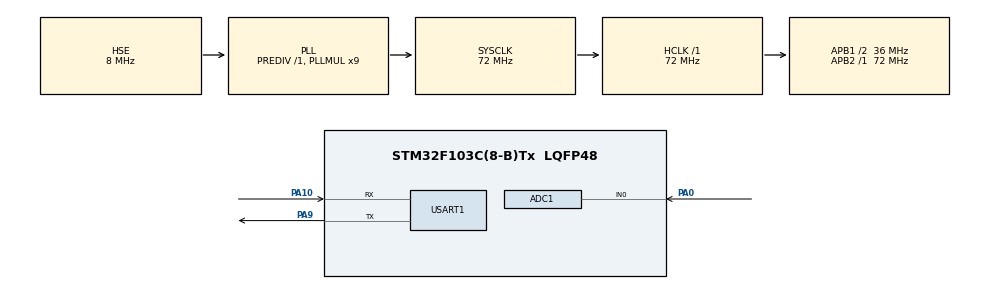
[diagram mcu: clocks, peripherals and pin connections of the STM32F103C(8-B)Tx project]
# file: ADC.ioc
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ADC1.Channel-0\#ChannelRegularConversion=ADC_CHANNEL_0
ADC1.ExternalTrigConv=ADC_EXTERNALTRIGCONV_T3_TRGO
ADC1.NbrOfConversionFlag=1
ADC1.Rank-0\#ChannelRegularConversion=1
ADC1.SamplingTime-0\#ChannelRegularConversion=ADC_SAMPLETIME_1CYCLE_5
ADC1.master=1
Dma.ADC1.0.Direction=DMA_PERIPH_TO_MEMORY
Dma.ADC1.0.Instance=DMA1_Channel1
Dma.ADC1.0.MemDataAlignment=DMA_MDATAALIGN_HALFWORD
Dma.ADC1.0.MemInc=DMA_MINC_ENABLE
Dma.ADC1.0.Mode=DMA_CIRCULAR
Dma.ADC1.0.PeriphDataAlignment=DMA_PDATAALIGN_HALFWORD
Dma.ADC1.0.PeriphInc=DMA_PINC_DISABLE
Dma.ADC1.0.Priority=DMA_PRIORITY_LOW
Dma.Request0=ADC1
Dma.Request1=USART1_RX
Dma.Request2=USART1_TX
Dma.USART1_RX.1.Direction=DMA_PERIPH_TO_MEMORY
Dma.USART1_RX.1.Instance=DMA1_Channel5
Dma.USART1_RX.1.MemDataAlignment=DMA_MDATAALIGN_BYTE
Dma.USART1_RX.1.MemInc=DMA_MINC_ENABLE
Dma.USART1_RX.1.Mode=DMA_NORMAL
Dma.USART1_RX.1.PeriphDataAlignment=DMA_PDATAALIGN_BYTE
Dma.USART1_RX.1.PeriphInc=DMA_PINC_DISABLE
Dma.USART1_RX.1.Priority=DMA_PRIORITY_LOW
Dma.USART1_TX.2.Direction=DMA_MEMORY_TO_PERIPH
Dma.USART1_TX.2.Instance=DMA1_Channel4
Dma.USART1_TX.2.MemDataAlignment=DMA_MDATAALIGN_BYTE
Dma.USART1_TX.2.MemInc=DMA_MINC_ENABLE
Dma.USART1_TX.2.Mode=DMA_NORMAL
Dma.USART1_TX.2.PeriphDataAlignment=DMA_PDATAALIGN_BYTE
Dma.USART1_TX.2.PeriphInc=DMA_PINC_DISABLE
Dma.USART1_TX.2.Priority=DMA_PRIORITY_LOW
Mcu.Family=STM32F1
Mcu.Name=STM32F103C(8-B)Tx
Mcu.Package=LQFP48
NVIC.ADC1_2_IRQn=true\:0\:0\:false\:false\:true\:true\:true
NVIC.DMA1_Channel1_IRQn=true\:0\:0\:false\:false\:true\:false\:true
NVIC.DMA1_Channel4_IRQn=true\:0\:0\:false\:false\:true\:false\:true
NVIC.DMA1_Channel5_IRQn=true\:0\:0\:false\:false\:true\:false\:true
NVIC.PriorityGroup=NVIC_PRIORITYGROUP_4
NVIC.TIM3_IRQn=true\:0\:0\:false\:false\:true\:true\:true
NVIC.USART1_IRQn=true\:0\:0\:false\:false\:true\:true\:true
PA0-WKUP.Signal=ADCx_IN0
PA10.Mode=Asynchronous
PA10.Signal=USART1_RX
PA13.Mode=Serial_Wire
PA13.Signal=SYS_JTMS-SWDIO
PA14.Mode=Serial_Wire
PA14.Signal=SYS_JTCK-SWCLK
PA9.Mode=Asynchronous
PA9.Signal=USART1_TX
PC14-OSC32_IN.Mode=LSE-External-Oscillator
PC14-OSC32_IN.Signal=RCC_OSC32_IN
PC15-OSC32_OUT.Mode=LSE-External-Oscillator
PC15-OSC32_OUT.Signal=RCC_OSC32_OUT
PD0-OSC_IN.Mode=HSE-External-Oscillator
PD0-OSC_IN.Signal=RCC_OSC_IN
PD1-OSC_OUT.Mode=HSE-External-Oscillator
PD1-OSC_OUT.Signal=RCC_OSC_OUT
ProjectManager.HeapSize=0x200
ProjectManager.StackSize=0x400
ProjectManager.TargetToolchain=MDK-ARM V5.32
RCC.ADCPresc=RCC_ADCPCLK2_DIV6
RCC.AHBFreq_Value=72000000
RCC.APB1CLKDivider=RCC_HCLK_DIV2
RCC.APB1Freq_Value=36000000
RCC.APB1TimFreq_Value=72000000
RCC.APB2Freq_Value=72000000
RCC.APB2TimFreq_Value=72000000
RCC.HCLKFreq_Value=72000000
RCC.PLLMUL=RCC_PLL_MUL9
RCC.PLLSourceVirtual=RCC_PLLSOURCE_HSE
RCC.SYSCLKFreq_VALUE=72000000
RCC.SYSCLKSource=RCC_SYSCLKSOURCE_PLLCLK
RCC.USBFreq_Value=72000000
SH.ADCx_IN0.0=ADC1_IN0,IN0
TIM3.Period=9999
TIM3.Prescaler=7200-1
TIM3.TIM_MasterOutputTrigger=TIM_TRGO_UPDATE
USART1.VirtualMode=VM_ASYNC
VP_TIM3_VS_ClockSourceINT.Mode=Internal
board=custom

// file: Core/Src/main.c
/* USER CODE BEGIN Header */
/**
  ******************************************************************************
  * @file           : main.c
  * @brief          : Main program body
  ******************************************************************************
  * @attention
  *
  * <h2><center>&copy; Copyright (c) 2026 STMicroelectronics.
  * All rights reserved.</center></h2>
  *
  * This software component is licensed by ST under BSD 3-Clause license,
  * the "License"; You may not use this file except in compliance with the
  * License. You may obtain a copy of the License at:
  *                        opensource.org/licenses/BSD-3-Clause
  *
  ******************************************************************************
  */
/* USER CODE END Header */
#include "main.h"
#include "adc.h"
#include "dma.h"
#include "tim.h"
#include "usart.h"
#include "gpio.h"

/* USER CODE BEGIN Includes */
#include "stdio.h"
/* USER CODE END Includes */

void SystemClock_Config(void);

/* USER CODE BEGIN 0 */
uint8_t DMA_data[1]={0};
uint16_t value=0;
uint16_t vol=0;
uint8_t Tx_buf[64]={0};
uint16_t data=0;
void HAL_ADC_ConvCpltCallback(ADC_HandleTypeDef* hadc)
{
	if(hadc->Instance==ADC1 )
	{
		value=DMA_data[0];
		vol=value*330/4096;
		if(value<5)
		{
			data=1;
		}
		else if(value>5&&value<50)
		{
			data=2;
		}
		else if(value>50&&value<100)
		{
			data=3;
		}
		else if(value>100)
		{
			data=4;
		}
		switch(data)
		{
			case 1:
				sprintf((char *)Tx_buf ,"黑暗，原始值为：%d\r\n",value);
			break;
			case 2:
				sprintf((char *)Tx_buf ,"弱光，原始值为：%d\r\n",value);
			break;
			case 3:
				sprintf((char *)Tx_buf ,"正常，原始值为：%d\r\n",value);
			break;
			case 4:
				sprintf((char *)Tx_buf ,"强光，原始值为：%d\r\n",value);
			break;
		}
		HAL_UART_Transmit_DMA(&huart1 ,Tx_buf,sizeof(Tx_buf ));
	}
}
/* USER CODE END 0 */

int main(void)
{

  /* MCU Configuration--------------------------------------------------------*/

  /* Reset of all peripherals, Initializes the Flash interface and the Systick. */
  HAL_Init();

  /* Configure the system clock */
  SystemClock_Config();

  /* Initialize all configured peripherals */
  MX_GPIO_Init();
  MX_DMA_Init();
  MX_ADC1_Init();
  MX_USART1_UART_Init();
  MX_TIM3_Init();
  /* USER CODE BEGIN 2 */
	HAL_TIM_Base_Start(&htim3 );
	HAL_ADC_Start_DMA(&hadc1,(uint32_t *)DMA_data,1);
  /* USER CODE END 2 */

  /* Infinite loop */
  while (1)
  {

  }
}

void SystemClock_Config(void)
{
  RCC_OscInitTypeDef RCC_OscInitStruct = {0};
  RCC_ClkInitTypeDef RCC_ClkInitStruct = {0};
  RCC_PeriphCLKInitTypeDef PeriphClkInit = {0};

  /** Initializes the RCC Oscillators according to the specified parameters
  * in the RCC_OscInitTypeDef structure.
  */
  RCC_OscInitStruct.OscillatorType = RCC_OSCILLATORTYPE_HSE;
  RCC_OscInitStruct.HSEState = RCC_HSE_ON;
  RCC_OscInitStruct.HSEPredivValue = RCC_HSE_PREDIV_DIV1;
  RCC_OscInitStruct.HSIState = RCC_HSI_ON;
  RCC_OscInitStruct.PLL.PLLState = RCC_PLL_ON;
  RCC_OscInitStruct.PLL.PLLSource = RCC_PLLSOURCE_HSE;
  RCC_OscInitStruct.PLL.PLLMUL = RCC_PLL_MUL9;
  if (HAL_RCC_OscConfig(&RCC_OscInitStruct) != HAL_OK)
  {
    Error_Handler();
  }
  /** Initializes the CPU, AHB and APB buses clocks
  */
  RCC_ClkInitStruct.ClockType = RCC_CLOCKTYPE_HCLK|RCC_CLOCKTYPE_SYSCLK
                              |RCC_CLOCKTYPE_PCLK1|RCC_CLOCKTYPE_PCLK2;
  RCC_ClkInitStruct.SYSCLKSource = RCC_SYSCLKSOURCE_PLLCLK;
  RCC_ClkInitStruct.AHBCLKDivider = RCC_SYSCLK_DIV1;
  RCC_ClkInitStruct.APB1CLKDivider = RCC_HCLK_DIV2;
  RCC_ClkInitStruct.APB2CLKDivider = RCC_HCLK_DIV1;

  if (HAL_RCC_ClockConfig(&RCC_ClkInitStruct, FLASH_LATENCY_2) != HAL_OK)
  {
    Error_Handler();
  }
  PeriphClkInit.PeriphClockSelection = RCC_PERIPHCLK_ADC;
  PeriphClkInit.AdcClockSelection = RCC_ADCPCLK2_DIV6;
  if (HAL_RCCEx_PeriphCLKConfig(&PeriphClkInit) != HAL_OK)
  {
    Error_Handler();
  }
}

void Error_Handler(void)
{
  __disable_irq();
  while (1)
  {
  }
}

/************************ (C) COPYRIGHT STMicroelectronics *****END OF FILE****/
